AUTOSAR XML (schema 4-0-3)
standard types defined: UInt16
package /AUTOSAR_Platform/DataConstrs
  range DC_UInt16: raw 0..65535
package /PATAC/EEPROM/BaseType
  base type PJB_UInt16: category=FIXED_LENGTH, base-type-size=16, base-type-encoding=NONE, native-declaration=unsigned short
package /PATAC/EEPROM/ImplementationDataType
  impl type EEP_Uint16: category=VALUE, base-type=PJB_UInt16, sw-calibration-access=READ-ONLY, type-emitter=RTE
package /PATAC/MSM/ComponentTypes
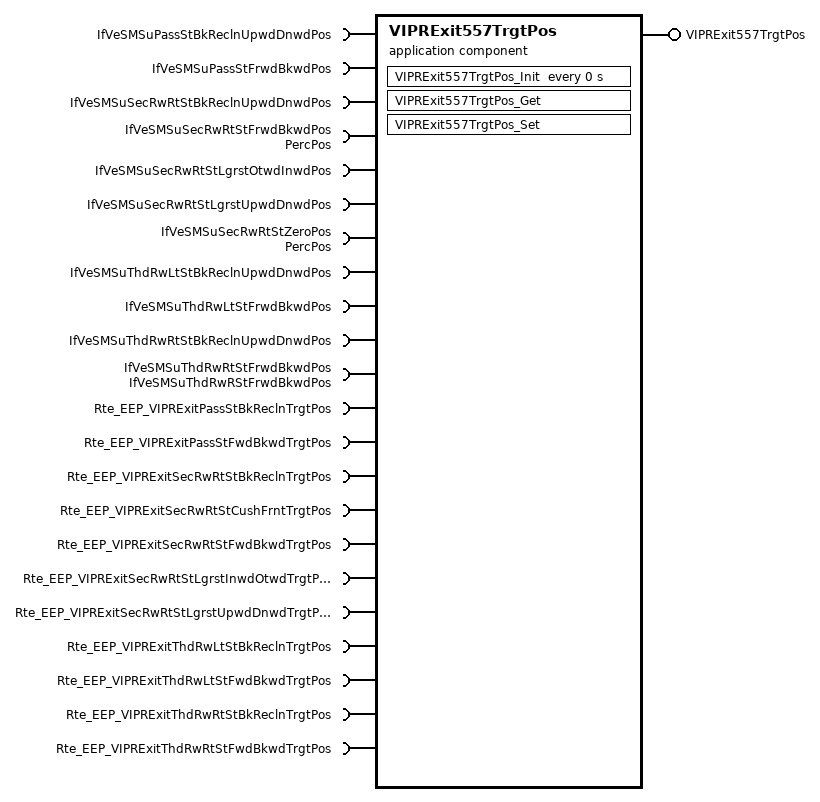
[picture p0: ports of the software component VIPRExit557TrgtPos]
  application sw component type VIPRExit557TrgtPos
    provide port VIPRExit557TrgtPos: provided-com-specs=[{operation=VIPRExit557TrgtPos/Get, queue-length=1}, {operation=VIPRExit557TrgtPos/Set, queue-length=1}], provided-interface=VIPRExit557TrgtPos
    22 x require port:
      IfVeSMSuPassStBkReclnUpwdDnwdPos: nonqueued-receiver-com-spec{data-element=IfVeSMSuPassStBkReclnUpwdDnwdPos/Val, filter=data-filter-type=ALWAYS, init-value=0}, required-interface=IfVeSMSuPassStBkReclnUpwdDnwdPos
      IfVeSMSuPassStFrwdBkwdPos: nonqueued-receiver-com-spec{data-element=IfVeSMSuPassStFrwdBkwdPos/Val, filter=data-filter-type=ALWAYS, init-value=0}, required-interface=IfVeSMSuPassStFrwdBkwdPos
      IfVeSMSuSecRwRtStBkReclnUpwdDnwdPos: nonqueued-receiver-com-spec{data-element=IfVeSMSuSecRwRtStBkReclnUpwdDnwdPos/Val, filter=data-filter-type=ALWAYS, init-value=0}, required-interface=IfVeSMSuSecRwRtStBkReclnUpwdDnwdPos
      IfVeSMSuSecRwRtStFrwdBkwdPos: nonqueued-receiver-com-spec{data-element=PercPos/Val, filter=data-filter-type=ALWAYS, init-value=0}, required-interface=PercPos
      IfVeSMSuSecRwRtStLgrstOtwdInwdPos: nonqueued-receiver-com-spec{data-element=IfVeSMSuSecRwRtStLgrstOtwdInwdPos/Val, filter=data-filter-type=ALWAYS, init-value=0}, required-interface=IfVeSMSuSecRwRtStLgrstOtwdInwdPos
      IfVeSMSuSecRwRtStLgrstUpwdDnwdPos: nonqueued-receiver-com-spec{data-element=IfVeSMSuSecRwRtStLgrstUpwdDnwdPos/Val, filter=data-filter-type=ALWAYS, init-value=0}, required-interface=IfVeSMSuSecRwRtStLgrstUpwdDnwdPos
      IfVeSMSuSecRwRtStZeroPos: nonqueued-receiver-com-spec{data-element=PercPos/Val, filter=data-filter-type=ALWAYS, init-value=0}, required-interface=PercPos
      IfVeSMSuThdRwLtStBkReclnUpwdDnwdPos: nonqueued-receiver-com-spec{data-element=IfVeSMSuThdRwLtStBkReclnUpwdDnwdPos/Val, filter=data-filter-type=ALWAYS, init-value=0}, required-interface=IfVeSMSuThdRwLtStBkReclnUpwdDnwdPos
      IfVeSMSuThdRwLtStFrwdBkwdPos: nonqueued-receiver-com-spec{data-element=IfVeSMSuThdRwLtStFrwdBkwdPos/Val, filter=data-filter-type=ALWAYS, init-value=0}, required-interface=IfVeSMSuThdRwLtStFrwdBkwdPos
      IfVeSMSuThdRwRtStBkReclnUpwdDnwdPos: nonqueued-receiver-com-spec{data-element=IfVeSMSuThdRwRtStBkReclnUpwdDnwdPos/Val, filter=data-filter-type=ALWAYS, init-value=0}, required-interface=IfVeSMSuThdRwRtStBkReclnUpwdDnwdPos
      IfVeSMSuThdRwRtStFrwdBkwdPos: nonqueued-receiver-com-spec{data-element=IfVeSMSuThdRwRStFrwdBkwdPos/Val, filter=data-filter-type=ALWAYS, init-value=0}, required-interface=IfVeSMSuThdRwRStFrwdBkwdPos
      Rte_EEP_VIPRExitPassStBkReclnTrgtPos: required-com-specs=[Rte_EEP_VIPRExitPassStBkReclnTrgtPos/Get, Rte_EEP_VIPRExitPassStBkReclnTrgtPos/Set], required-interface=Rte_EEP_VIPRExitPassStBkReclnTrgtPos
      Rte_EEP_VIPRExitPassStFwdBkwdTrgtPos: required-com-specs=[Rte_EEP_VIPRExitPassStFwdBkwdTrgtPos/Get, Rte_EEP_VIPRExitPassStFwdBkwdTrgtPos/Set], required-interface=Rte_EEP_VIPRExitPassStFwdBkwdTrgtPos
      Rte_EEP_VIPRExitSecRwRtStBkReclnTrgtPos: required-com-specs=[Rte_EEP_VIPRExitSecRwRtStBkReclnTrgtPos/Get, Rte_EEP_VIPRExitSecRwRtStBkReclnTrgtPos/Set], required-interface=Rte_EEP_VIPRExitSecRwRtStBkReclnTrgtPos
      Rte_EEP_VIPRExitSecRwRtStCushFrntTrgtPos: required-com-specs=[Rte_EEP_VIPRExitSecRwRtStCushFrntTrgtPos/Get, Rte_EEP_VIPRExitSecRwRtStCushFrntTrgtPos/Set], required-interface=Rte_EEP_VIPRExitSecRwRtStCushFrntTrgtPos
      Rte_EEP_VIPRExitSecRwRtStFwdBkwdTrgtPos: required-com-specs=[Rte_EEP_VIPRExitSecRwRtStFwdBkwdTrgtPos/Get, Rte_EEP_VIPRExitSecRwRtStFwdBkwdTrgtPos/Set], required-interface=Rte_EEP_VIPRExitSecRwRtStFwdBkwdTrgtPos
      Rte_EEP_VIPRExitSecRwRtStLgrstInwdOtwdTrgtPos: required-com-specs=[Rte_EEP_VIPRExitSecRwRtStLgrstInwdOtwdTrgtPos/Get, Rte_EEP_VIPRExitSecRwRtStLgrstInwdOtwdTrgtPos/Set], required-interface=Rte_EEP_VIPRExitSecRwRtStLgrstInwdOtwdTrgtPos
      Rte_EEP_VIPRExitSecRwRtStLgrstUpwdDnwdTrgtPos: required-com-specs=[Rte_EEP_VIPRExitSecRwRtStLgrstUpwdDnwdTrgtPos/Get, Rte_EEP_VIPRExitSecRwRtStLgrstUpwdDnwdTrgtPos/Set], required-interface=Rte_EEP_VIPRExitSecRwRtStLgrstUpwdDnwdTrgtPos
      Rte_EEP_VIPRExitThdRwLtStBkReclnTrgtPos: required-com-specs=[Rte_EEP_VIPRExitThdRwLtStBkReclnTrgtPos/Get, Rte_EEP_VIPRExitThdRwLtStBkReclnTrgtPos/Set], required-interface=Rte_EEP_VIPRExitThdRwLtStBkReclnTrgtPos
      Rte_EEP_VIPRExitThdRwLtStFwdBkwdTrgtPos: required-com-specs=[Rte_EEP_VIPRExitThdRwLtStFwdBkwdTrgtPos/Get, Rte_EEP_VIPRExitThdRwLtStFwdBkwdTrgtPos/Set], required-interface=Rte_EEP_VIPRExitThdRwLtStFwdBkwdTrgtPos
      Rte_EEP_VIPRExitThdRwRtStBkReclnTrgtPos: required-com-specs=[Rte_EEP_VIPRExitThdRwRtStBkReclnTrgtPos/Get, Rte_EEP_VIPRExitThdRwRtStBkReclnTrgtPos/Set], required-interface=Rte_EEP_VIPRExitThdRwRtStBkReclnTrgtPos
      Rte_EEP_VIPRExitThdRwRtStFwdBkwdTrgtPos: required-com-specs=[Rte_EEP_VIPRExitThdRwRtStFwdBkwdTrgtPos/Get, Rte_EEP_VIPRExitThdRwRtStFwdBkwdTrgtPos/Set], required-interface=Rte_EEP_VIPRExitThdRwRtStFwdBkwdTrgtPos
    behavior VIPRExit557TrgtPos_InternalBehavior
      operation invoked event OIT_VIPRExit557TrgtPos_Get_VIPRExit557TrgtPos_Get: start-on-event=VIPRExit557TrgtPos_Get, operation=VIPRExit557TrgtPos.Get
      timing event VIPRExit557TrgtPos_InitEvent: start-on-event=VIPRExit557TrgtPos_Init, period=0
      operation invoked event OIT_VIPRExit557TrgtPos_Set_VIPRExit557TrgtPos_Set: start-on-event=VIPRExit557TrgtPos_Set, operation=VIPRExit557TrgtPos.Set
      runnable VIPRExit557TrgtPos_Get
        11 x sync call, all with timeout=0:
          SC_Rte_EEP_VIPRExitPassStBkReclnTrgtPos_Get: operation=Rte_EEP_VIPRExitPassStBkReclnTrgtPos.Get
          SC_Rte_EEP_VIPRExitPassStFwdBkwdTrgtPos_Get: operation=Rte_EEP_VIPRExitPassStFwdBkwdTrgtPos.Get
          SC_Rte_EEP_VIPRExitSecRwRtStBkReclnTrgtPos_Get: operation=Rte_EEP_VIPRExitSecRwRtStBkReclnTrgtPos.Get
          SC_Rte_EEP_VIPRExitSecRwRtStCushFrntTrgtPos_Get: operation=Rte_EEP_VIPRExitSecRwRtStCushFrntTrgtPos.Get
          SC_Rte_EEP_VIPRExitSecRwRtStFwdBkwdTrgtPos_Get: operation=Rte_EEP_VIPRExitSecRwRtStFwdBkwdTrgtPos.Get
          SC_Rte_EEP_VIPRExitSecRwRtStLgrstInwdOtwdTrgtPos_Get: operation=Rte_EEP_VIPRExitSecRwRtStLgrstInwdOtwdTrgtPos.Get
          SC_Rte_EEP_VIPRExitSecRwRtStLgrstUpwdDnwdTrgtPos_Get: operation=Rte_EEP_VIPRExitSecRwRtStLgrstUpwdDnwdTrgtPos.Get
          SC_Rte_EEP_VIPRExitThdRwLtStBkReclnTrgtPos_Get: operation=Rte_EEP_VIPRExitThdRwLtStBkReclnTrgtPos.Get
          SC_Rte_EEP_VIPRExitThdRwLtStFwdBkwdTrgtPos_Get: operation=Rte_EEP_VIPRExitThdRwLtStFwdBkwdTrgtPos.Get
          SC_Rte_EEP_VIPRExitThdRwRtStBkReclnTrgtPos_Get: operation=Rte_EEP_VIPRExitThdRwRtStBkReclnTrgtPos.Get
          SC_Rte_EEP_VIPRExitThdRwRtStFwdBkwdTrgtPos_Get: operation=Rte_EEP_VIPRExitThdRwRtStFwdBkwdTrgtPos.Get
      runnable VIPRExit557TrgtPos_Init
      runnable VIPRExit557TrgtPos_Set
        data-receive-point-by-arguments:
          11 x access:
            REC_IfVeSMSuPassStBkReclnUpwdDnwdPos_Val: accessed-variable=IfVeSMSuPassStBkReclnUpwdDnwdPos.Val
            REC_IfVeSMSuPassStFrwdBkwdPos_Val: accessed-variable=IfVeSMSuPassStFrwdBkwdPos.Val
            REC_IfVeSMSuSecRwRtStBkReclnUpwdDnwdPos_Val: accessed-variable=IfVeSMSuSecRwRtStBkReclnUpwdDnwdPos.Val
            REC_IfVeSMSuSecRwRtStFrwdBkwdPos_Val: accessed-variable=IfVeSMSuSecRwRtStFrwdBkwdPos.Val
            REC_IfVeSMSuSecRwRtStLgrstOtwdInwdPos_Val: accessed-variable=IfVeSMSuSecRwRtStLgrstOtwdInwdPos.Val
            REC_IfVeSMSuSecRwRtStLgrstUpwdDnwdPos_Val: accessed-variable=IfVeSMSuSecRwRtStLgrstUpwdDnwdPos.Val
            REC_IfVeSMSuSecRwRtStZeroPos_Val: accessed-variable=IfVeSMSuSecRwRtStZeroPos.Val
            REC_IfVeSMSuThdRwLtStBkReclnUpwdDnwdPos_Val: accessed-variable=IfVeSMSuThdRwLtStBkReclnUpwdDnwdPos.Val
            REC_IfVeSMSuThdRwLtStFrwdBkwdPos_Val: accessed-variable=IfVeSMSuThdRwLtStFrwdBkwdPos.Val
            REC_IfVeSMSuThdRwRtStBkReclnUpwdDnwdPos_Val: accessed-variable=IfVeSMSuThdRwRtStBkReclnUpwdDnwdPos.Val
            REC_IfVeSMSuThdRwRtStFrwdBkwdPos_Val: accessed-variable=IfVeSMSuThdRwRtStFrwdBkwdPos.Val
        11 x sync call, all with timeout=0:
          SC_Rte_EEP_VIPRExitPassStBkReclnTrgtPos_Set: operation=Rte_EEP_VIPRExitPassStBkReclnTrgtPos.Set
          SC_Rte_EEP_VIPRExitPassStFwdBkwdTrgtPos_Set: operation=Rte_EEP_VIPRExitPassStFwdBkwdTrgtPos.Set
          SC_Rte_EEP_VIPRExitSecRwRtStBkReclnTrgtPos_Set: operation=Rte_EEP_VIPRExitSecRwRtStBkReclnTrgtPos.Set
          SC_Rte_EEP_VIPRExitSecRwRtStCushFrntTrgtPos_Set: operation=Rte_EEP_VIPRExitSecRwRtStCushFrntTrgtPos.Set
          SC_Rte_EEP_VIPRExitSecRwRtStFwdBkwdTrgtPos_Set: operation=Rte_EEP_VIPRExitSecRwRtStFwdBkwdTrgtPos.Set
          SC_Rte_EEP_VIPRExitSecRwRtStLgrstInwdOtwdTrgtPos_Set: operation=Rte_EEP_VIPRExitSecRwRtStLgrstInwdOtwdTrgtPos.Set
          SC_Rte_EEP_VIPRExitSecRwRtStLgrstUpwdDnwdTrgtPos_Set: operation=Rte_EEP_VIPRExitSecRwRtStLgrstUpwdDnwdTrgtPos.Set
          SC_Rte_EEP_VIPRExitThdRwLtStBkReclnTrgtPos_Set: operation=Rte_EEP_VIPRExitThdRwLtStBkReclnTrgtPos.Set
          SC_Rte_EEP_VIPRExitThdRwLtStFwdBkwdTrgtPos_Set: operation=Rte_EEP_VIPRExitThdRwLtStFwdBkwdTrgtPos.Set
          SC_Rte_EEP_VIPRExitThdRwRtStBkReclnTrgtPos_Set: operation=Rte_EEP_VIPRExitThdRwRtStBkReclnTrgtPos.Set
          SC_Rte_EEP_VIPRExitThdRwRtStFwdBkwdTrgtPos_Set: operation=Rte_EEP_VIPRExitThdRwRtStFwdBkwdTrgtPos.Set
  swc implementation VIPRExit557TrgtPos_Implementation: behavior=VIPRExit557TrgtPos_InternalBehavior
    code-descriptors:
      code Default: artifact-descriptors=autosar-engineering-object={short-label=Default, category=SWSRC}
package /PATAC/MSM/ModeAdjust/PortInterface
  client server interface VIPRExit557TrgtPos
    operation Get
      11 x arg, all with type=UInt16, direction=OUT, server-argument-impl-policy=USE-ARGUMENT-TYPE:
        SecRwRtStBkReclnTrgtPos
        SecRwRtStZeroTrgtPos
        SecRwRtStLgrstUpwdDnwdTrgtPos
        SecRwRtStLgrstInwdOtwdTrgtPos
        ThdRwLtStBkReclnTrgtPos
        ThdRwLtStFwdBkwdTrgtPos
        ThdRwRtStBkReclnTrgtPos
        ThdRwRtStFwdBkwdTrgtPos
        PassStBkReclnTrgtPos
        PassStFwdBkwdTrgtPos
        SecRwRtStFwdBkwdTrgtPos
    operation Set
  sender receiver interface PercPos: invalidation-policy{data-element=PercPos/Val, handle-invalid=DONT-INVALIDATE}
    data Val: type=UInt16
package /PATAC/MSM/PortInterfaces
  9 x sender receiver interface:
    IfVeSMSuPassStBkReclnUpwdDnwdPos: invalidation-policy{data-element=IfVeSMSuPassStBkReclnUpwdDnwdPos/Val, handle-invalid=DONT-INVALIDATE}
      data Val: type=UInt16
    IfVeSMSuPassStFrwdBkwdPos: invalidation-policy{data-element=IfVeSMSuPassStFrwdBkwdPos/Val, handle-invalid=DONT-INVALIDATE}
      data Val: type=UInt16
    IfVeSMSuSecRwRtStBkReclnUpwdDnwdPos: invalidation-policy{data-element=IfVeSMSuSecRwRtStBkReclnUpwdDnwdPos/Val, handle-invalid=DONT-INVALIDATE}
      data Val: type=UInt16
    IfVeSMSuSecRwRtStLgrstOtwdInwdPos: invalidation-policy{data-element=IfVeSMSuSecRwRtStLgrstOtwdInwdPos/Val, handle-invalid=DONT-INVALIDATE}
      data Val: type=UInt16
    IfVeSMSuSecRwRtStLgrstUpwdDnwdPos: invalidation-policy{data-element=IfVeSMSuSecRwRtStLgrstUpwdDnwdPos/Val, handle-invalid=DONT-INVALIDATE}
      data Val: type=UInt16
    IfVeSMSuThdRwLtStBkReclnUpwdDnwdPos: invalidation-policy{data-element=IfVeSMSuThdRwLtStBkReclnUpwdDnwdPos/Val, handle-invalid=DONT-INVALIDATE}
      data Val: type=UInt16
    IfVeSMSuThdRwLtStFrwdBkwdPos: invalidation-policy{data-element=IfVeSMSuThdRwLtStFrwdBkwdPos/Val, handle-invalid=DONT-INVALIDATE}
      data Val: type=UInt16
    IfVeSMSuThdRwRStFrwdBkwdPos: invalidation-policy{data-element=IfVeSMSuThdRwRStFrwdBkwdPos/Val, handle-invalid=DONT-INVALIDATE}
      data Val: type=UInt16
    IfVeSMSuThdRwRtStBkReclnUpwdDnwdPos: invalidation-policy{data-element=IfVeSMSuThdRwRtStBkReclnUpwdDnwdPos/Val, handle-invalid=DONT-INVALIDATE}
      data Val: type=UInt16
package /PortInterfaces
  11 x client server interface:
    Rte_EEP_VIPRExitPassStBkReclnTrgtPos
      operation Get
        arg arg: type=EEP_Uint16, direction=OUT, server-argument-impl-policy=USE-ARGUMENT-TYPE
      operation Set
        arg arg: type=EEP_Uint16, direction=IN, server-argument-impl-policy=USE-ARGUMENT-TYPE
    Rte_EEP_VIPRExitPassStFwdBkwdTrgtPos
      operation Get
        arg arg: type=EEP_Uint16, direction=OUT, server-argument-impl-policy=USE-ARGUMENT-TYPE
      operation Set
        arg arg: type=EEP_Uint16, direction=IN, server-argument-impl-policy=USE-ARGUMENT-TYPE
    Rte_EEP_VIPRExitSecRwRtStBkReclnTrgtPos
      operation Get
        arg arg: type=EEP_Uint16, direction=OUT, server-argument-impl-policy=USE-ARGUMENT-TYPE
      operation Set
        arg arg: type=EEP_Uint16, direction=IN, server-argument-impl-policy=USE-ARGUMENT-TYPE
    Rte_EEP_VIPRExitSecRwRtStCushFrntTrgtPos
      operation Get
        arg arg: type=EEP_Uint16, direction=OUT, server-argument-impl-policy=USE-ARGUMENT-TYPE
      operation Set
        arg arg: type=EEP_Uint16, direction=IN, server-argument-impl-policy=USE-ARGUMENT-TYPE
    Rte_EEP_VIPRExitSecRwRtStFwdBkwdTrgtPos
      operation Get
        arg arg: type=EEP_Uint16, direction=OUT, server-argument-impl-policy=USE-ARGUMENT-TYPE
      operation Set
        arg arg: type=EEP_Uint16, direction=IN, server-argument-impl-policy=USE-ARGUMENT-TYPE
    Rte_EEP_VIPRExitSecRwRtStLgrstInwdOtwdTrgtPos
      operation Get
        arg arg: type=EEP_Uint16, direction=OUT, server-argument-impl-policy=USE-ARGUMENT-TYPE
      operation Set
        arg arg: type=EEP_Uint16, direction=IN, server-argument-impl-policy=USE-ARGUMENT-TYPE
    Rte_EEP_VIPRExitSecRwRtStLgrstUpwdDnwdTrgtPos
      operation Get
        arg arg: type=EEP_Uint16, direction=OUT, server-argument-impl-policy=USE-ARGUMENT-TYPE
      operation Set
        arg arg: type=EEP_Uint16, direction=IN, server-argument-impl-policy=USE-ARGUMENT-TYPE
    Rte_EEP_VIPRExitThdRwLtStBkReclnTrgtPos
      operation Get
        arg arg: type=EEP_Uint16, direction=OUT, server-argument-impl-policy=USE-ARGUMENT-TYPE
      operation Set
        arg arg: type=EEP_Uint16, direction=IN, server-argument-impl-policy=USE-ARGUMENT-TYPE
    Rte_EEP_VIPRExitThdRwLtStFwdBkwdTrgtPos
      operation Get
        arg arg: type=EEP_Uint16, direction=OUT, server-argument-impl-policy=USE-ARGUMENT-TYPE
      operation Set
        arg arg: type=EEP_Uint16, direction=IN, server-argument-impl-policy=USE-ARGUMENT-TYPE
    Rte_EEP_VIPRExitThdRwRtStBkReclnTrgtPos
      operation Get
        arg arg: type=EEP_Uint16, direction=OUT, server-argument-impl-policy=USE-ARGUMENT-TYPE
      operation Set
        arg arg: type=EEP_Uint16, direction=IN, server-argument-impl-policy=USE-ARGUMENT-TYPE
    Rte_EEP_VIPRExitThdRwRtStFwdBkwdTrgtPos
      operation Get
        arg arg: type=EEP_Uint16, direction=OUT, server-argument-impl-policy=USE-ARGUMENT-TYPE
      operation Set
        arg arg: type=EEP_Uint16, direction=IN, server-argument-impl-policy=USE-ARGUMENT-TYPE
